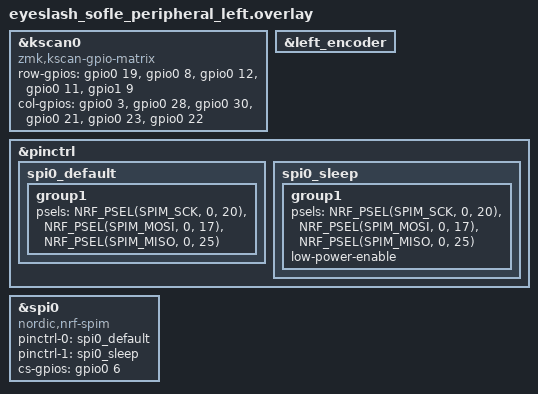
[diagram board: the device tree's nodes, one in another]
/*
*
* Copyright (c) 2021 Darryl deHaan
* SPDX-License-Identifier: MIT
*
*/

#include "eyeslash_sofle.dtsi"

&kscan0 {
    compatible = "zmk,kscan-gpio-matrix";
    row-gpios
        = <&gpio0 19 (GPIO_ACTIVE_HIGH | GPIO_PULL_DOWN)>
        , <&gpio0 8 (GPIO_ACTIVE_HIGH | GPIO_PULL_DOWN)>
        , <&gpio0 12 (GPIO_ACTIVE_HIGH | GPIO_PULL_DOWN)>
        , <&gpio0 11 (GPIO_ACTIVE_HIGH | GPIO_PULL_DOWN)>
        , <&gpio1 9 (GPIO_ACTIVE_HIGH | GPIO_PULL_DOWN)>
        ;
    col-gpios
        = <&gpio0 3 GPIO_ACTIVE_HIGH>
        , <&gpio0 28 GPIO_ACTIVE_HIGH>
        , <&gpio0 30 GPIO_ACTIVE_HIGH>
        , <&gpio0 21 GPIO_ACTIVE_HIGH>
        , <&gpio0 23 GPIO_ACTIVE_HIGH>
        , <&gpio0 22 GPIO_ACTIVE_HIGH>
        ;
};

&left_encoder {
    status = "okay";
};

&pinctrl {

    spi0_default: spi0_default {
        group1 {
            psels = <NRF_PSEL(SPIM_SCK, 0, 20)>,
                <NRF_PSEL(SPIM_MOSI, 0, 17)>,
                <NRF_PSEL(SPIM_MISO, 0, 25)>;
        };
    };

    spi0_sleep: spi0_sleep {
        group1 {
            psels = <NRF_PSEL(SPIM_SCK, 0, 20)>,
                <NRF_PSEL(SPIM_MOSI, 0, 17)>,
                <NRF_PSEL(SPIM_MISO, 0, 25)>;
            low-power-enable;
        };
    };
};

nice_view_spi: &spi0 {
    compatible = "nordic,nrf-spim";
    pinctrl-0 = <&spi0_default>;
    pinctrl-1 = <&spi0_sleep>;
    pinctrl-names = "default", "sleep";
    cs-gpios = <&gpio0 6 GPIO_ACTIVE_HIGH>;
};
